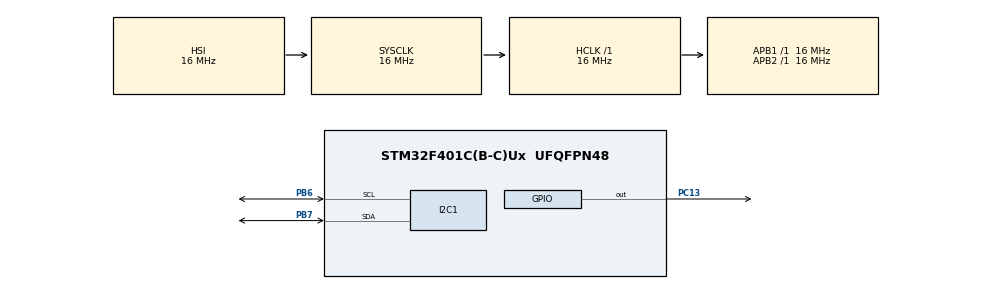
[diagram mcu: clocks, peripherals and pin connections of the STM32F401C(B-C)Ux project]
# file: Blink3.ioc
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Mcu.Family=STM32F4
Mcu.Name=STM32F401C(B-C)Ux
Mcu.Package=UFQFPN48
NVIC.I2C1_ER_IRQn=true\:0\:0\:false\:false\:true\:true\:true\:true
NVIC.I2C1_EV_IRQn=true\:0\:0\:false\:false\:true\:true\:true\:true
NVIC.PriorityGroup=NVIC_PRIORITYGROUP_4
NVIC.TIM1_UP_TIM10_IRQn=true\:0\:0\:false\:false\:true\:true\:true\:true
PA13.Mode=Serial_Wire
PA13.Signal=SYS_JTMS-SWDIO
PA14.Mode=Serial_Wire
PA14.Signal=SYS_JTCK-SWCLK
PB6.Mode=I2C
PB6.Signal=I2C1_SCL
PB7.Mode=I2C
PB7.Signal=I2C1_SDA
PC13-ANTI_TAMP.Signal=GPIO_Output
ProjectManager.HeapSize=0x200
ProjectManager.StackSize=0x400
ProjectManager.TargetToolchain=STM32CubeIDE
RCC.48MHZClocksFreq_Value=42000000
RCC.AHBFreq_Value=16000000
RCC.APB1Freq_Value=16000000
RCC.APB1TimFreq_Value=16000000
RCC.APB2Freq_Value=16000000
RCC.APB2TimFreq_Value=16000000
RCC.CortexFreq_Value=16000000
RCC.HCLKFreq_Value=16000000
RCC.HSE_VALUE=25000000
RCC.HSI_VALUE=16000000
RCC.LSE_VALUE=32768
RCC.PLLN=168
RCC.SYSCLKFreq_VALUE=16000000
RCC.VCOOutputFreq_Value=168000000
TIM10.Prescaler=80-1
VP_TIM10_VS_ClockSourceINT.Mode=Enable_Timer
board=custom

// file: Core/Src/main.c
/* USER CODE BEGIN Header */
/**
  ******************************************************************************
  * @file           : main.c
  * @brief          : Main program body
  ******************************************************************************
  * @attention
  *
  * Copyright (c) 2022 STMicroelectronics.
  * All rights reserved.
  *
  * This software is licensed under terms that can be found in the LICENSE file
  * in the root directory of this software component.
  * If no LICENSE file comes with this software, it is provided AS-IS.
  *
  ******************************************************************************
  */
/* USER CODE END Header */
#include "main.h"

/* USER CODE BEGIN Includes */
#include "PCF8574_LCD.h"
/* USER CODE END Includes */

/* USER CODE BEGIN PD */
#define AHT10_ADDRESS (0x38 << 1) // 0b11100000; Adress[7-bit]Wite/Read[1-bit]
/* USER CODE END PD */

 I2C_HandleTypeDef hi2c1;

TIM_HandleTypeDef htim10;

/* USER CODE BEGIN PV */
uint8_t 	T_100ms = 255;

int hundreds;
int tens;
int ones;

float temperature;
#define TEMP		1
#define HUMIDITY 	0
// uint8_t AHT10_Switcher = 255;

/* USER CODE END PV */

void SystemClock_Config(void);
static void MX_GPIO_Init(void);
static void MX_TIM10_Init(void);
static void MX_I2C1_Init(void);

/* USER CODE BEGIN 0 */
//void HAL_TIM_PeriodElapsedCallback( TIM_HandleTypeDef *htim )
//{
//	if (htim->Instance == TIM10) {
//	/* Set every 100ms */
//	T_100ms = 255;
// }
//}

//void HAL_I2C_MasterTxCpltCallback(I2C_HandleTypeDef *hi2c) {
//
////	I2C_TypeDef *a;
////	a = hi2c->Instance;
//
//
//	AHT10_Switcher = ~AHT10_Switcher;
//}

/* USER CODE END 0 */

int main(void)
{

  /* MCU Configuration--------------------------------------------------------*/

  /* Reset of all peripherals, Initializes the Flash interface and the Systick. */
  HAL_Init();

  /* Configure the system clock */
  SystemClock_Config();

  /* Initialize all configured peripherals */
  MX_GPIO_Init();
  MX_TIM10_Init();
  MX_I2C1_Init();
  /* USER CODE BEGIN 2 */

  LCD_Init ( hi2c1 );
  LCD_Clear ( hi2c1 );
  LCD_Put_Cur ( 0, 0, hi2c1 );
  LCD_Send_String ( "TEMP: ", hi2c1 );

  HAL_TIM_Base_Start_IT ( &htim10 );
  /* USER CODE END 2 */

  /* Infinite loop */
  /* USER CODE BEGIN WHILE */
	while (1) {
//		if (AHT10_Switcher) {
			temperature = ATH10_Get_Temperature(hi2c1, AHT10_ADDRESS, 1);

			ones = temperature % 10;
			temperature = temperature / 10;
			tens = temperature % 10;
			hundreds = temperature / 10;

			LCD_Put_Cur(0, 7, hi2c1);
			LCD_Send_Data((ones | 0x30), hi2c1);
			LCD_Put_Cur(0, 6, hi2c1);
			LCD_Send_Data((tens | 0x30), hi2c1);

			HAL_Delay(1000);
			T_100ms = 0;
//		}

	}
    /* USER CODE END WHILE */

}

void SystemClock_Config(void)
{
  RCC_OscInitTypeDef RCC_OscInitStruct = {0};
  RCC_ClkInitTypeDef RCC_ClkInitStruct = {0};

  /** Configure the main internal regulator output voltage
  */
  __HAL_RCC_PWR_CLK_ENABLE();
  __HAL_PWR_VOLTAGESCALING_CONFIG(PWR_REGULATOR_VOLTAGE_SCALE2);

  /** Initializes the RCC Oscillators according to the specified parameters
  * in the RCC_OscInitTypeDef structure.
  */
  RCC_OscInitStruct.OscillatorType = RCC_OSCILLATORTYPE_HSI;
  RCC_OscInitStruct.HSIState = RCC_HSI_ON;
  RCC_OscInitStruct.HSICalibrationValue = RCC_HSICALIBRATION_DEFAULT;
  RCC_OscInitStruct.PLL.PLLState = RCC_PLL_NONE;
  if (HAL_RCC_OscConfig(&RCC_OscInitStruct) != HAL_OK)
  {
    Error_Handler();
  }

  /** Initializes the CPU, AHB and APB buses clocks
  */
  RCC_ClkInitStruct.ClockType = RCC_CLOCKTYPE_HCLK|RCC_CLOCKTYPE_SYSCLK
                              |RCC_CLOCKTYPE_PCLK1|RCC_CLOCKTYPE_PCLK2;
  RCC_ClkInitStruct.SYSCLKSource = RCC_SYSCLKSOURCE_HSI;
  RCC_ClkInitStruct.AHBCLKDivider = RCC_SYSCLK_DIV1;
  RCC_ClkInitStruct.APB1CLKDivider = RCC_HCLK_DIV1;
  RCC_ClkInitStruct.APB2CLKDivider = RCC_HCLK_DIV1;

  if (HAL_RCC_ClockConfig(&RCC_ClkInitStruct, FLASH_LATENCY_0) != HAL_OK)
  {
    Error_Handler();
  }
}

static void MX_I2C1_Init(void)
{

  hi2c1.Instance = I2C1;
  hi2c1.Init.ClockSpeed = 100000;
  hi2c1.Init.DutyCycle = I2C_DUTYCYCLE_2;
  hi2c1.Init.OwnAddress1 = 0;
  hi2c1.Init.AddressingMode = I2C_ADDRESSINGMODE_7BIT;
  hi2c1.Init.DualAddressMode = I2C_DUALADDRESS_DISABLE;
  hi2c1.Init.OwnAddress2 = 0;
  hi2c1.Init.GeneralCallMode = I2C_GENERALCALL_DISABLE;
  hi2c1.Init.NoStretchMode = I2C_NOSTRETCH_DISABLE;
  if (HAL_I2C_Init(&hi2c1) != HAL_OK)
  {
    Error_Handler();
  }

}

static void MX_TIM10_Init(void)
{

  htim10.Instance = TIM10;
  htim10.Init.Prescaler = 80-1;
  htim10.Init.CounterMode = TIM_COUNTERMODE_UP;
  htim10.Init.Period = 65535;
  htim10.Init.ClockDivision = TIM_CLOCKDIVISION_DIV1;
  htim10.Init.AutoReloadPreload = TIM_AUTORELOAD_PRELOAD_DISABLE;
  if (HAL_TIM_Base_Init(&htim10) != HAL_OK)
  {
    Error_Handler();
  }

}

static void MX_GPIO_Init(void)
{
  GPIO_InitTypeDef GPIO_InitStruct = {0};

  /* GPIO Ports Clock Enable */
  __HAL_RCC_GPIOC_CLK_ENABLE();
  __HAL_RCC_GPIOA_CLK_ENABLE();
  __HAL_RCC_GPIOB_CLK_ENABLE();

  /*Configure GPIO pin Output Level */
  HAL_GPIO_WritePin(GPIOC, GPIO_PIN_13, GPIO_PIN_RESET);

  /*Configure GPIO pin : PC13 */
  GPIO_InitStruct.Pin = GPIO_PIN_13;
  GPIO_InitStruct.Mode = GPIO_MODE_OUTPUT_PP;
  GPIO_InitStruct.Pull = GPIO_NOPULL;
  GPIO_InitStruct.Speed = GPIO_SPEED_FREQ_LOW;
  HAL_GPIO_Init(GPIOC, &GPIO_InitStruct);

}

void Error_Handler(void)
{
  __disable_irq();
  while (1)
  {
  }
}
